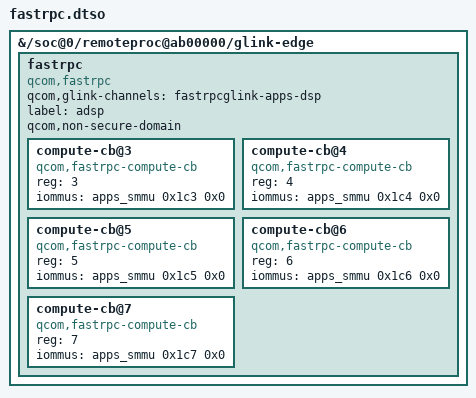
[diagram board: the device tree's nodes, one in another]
// SPDX-License-Identifier: GPL-2.0-only
/dts-v1/;
/plugin/;
/ { fragment@0 { target-path = "/soc@0/remoteproc@ab00000/glink-edge"; __overlay__ {
				fastrpc {
					compatible = "qcom,fastrpc";
					qcom,glink-channels = "fastrpcglink-apps-dsp";
					label = "adsp";

					qcom,non-secure-domain;

					#address-cells = <1>;
					#size-cells = <0>;

					compute-cb@3 {
						compatible = "qcom,fastrpc-compute-cb";
						reg = <3>;
						iommus = <&apps_smmu 0x1c3 0x0>;
					};

					compute-cb@4 {
						compatible = "qcom,fastrpc-compute-cb";
						reg = <4>;
						iommus = <&apps_smmu 0x1c4 0x0>;
					};

					compute-cb@5 {
						compatible = "qcom,fastrpc-compute-cb";
						reg = <5>;
						iommus = <&apps_smmu 0x1c5 0x0>;
					};

					compute-cb@6 {
						compatible = "qcom,fastrpc-compute-cb";
						reg = <6>;
						iommus = <&apps_smmu 0x1c6 0x0>;
					};

					compute-cb@7 {
						compatible = "qcom,fastrpc-compute-cb";
						reg = <7>;
						iommus = <&apps_smmu 0x1c7 0x0>;
					};
				};
}; }; };
